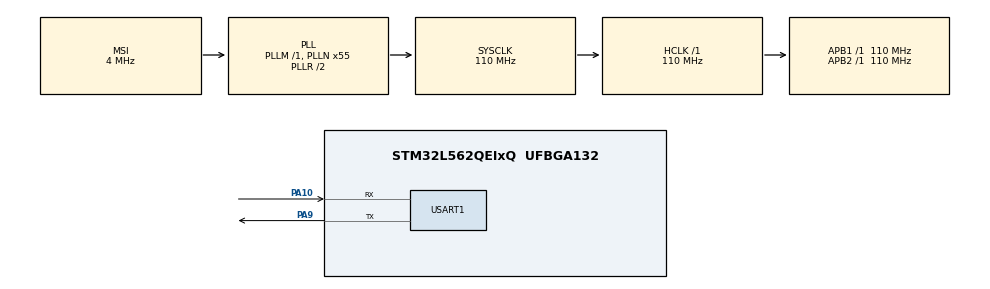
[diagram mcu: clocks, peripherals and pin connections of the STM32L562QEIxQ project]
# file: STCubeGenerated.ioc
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Mcu.Family=STM32L5
Mcu.Name=STM32L562QEIxQ
Mcu.Package=UFBGA132
Mcu.TrustZone=disable
NVIC.PriorityGroup=NVIC_PRIORITYGROUP_3
NVIC.USART1_IRQn=true\:0\:0\:false\:false\:true\:true\:true
PA10.GPIO_Speed=GPIO_SPEED_FREQ_VERY_HIGH
PA10.Mode=Asynchronous
PA10.Signal=USART1_RX
PA9.GPIO_Speed=GPIO_SPEED_FREQ_VERY_HIGH
PA9.Mode=Asynchronous
PA9.Signal=USART1_TX
ProjectManager.HeapSize=0x200
ProjectManager.StackSize=0x400
ProjectManager.TargetToolchain=MDK-ARM V5.27
RCC.AHBFreq_Value=110000000
RCC.APB1Freq_Value=110000000
RCC.APB1TimFreq_Value=110000000
RCC.APB2Freq_Value=110000000
RCC.APB2TimFreq_Value=110000000
RCC.CortexFreq_Value=110000000
RCC.HCLKFreq_Value=110000000
RCC.HSE_VALUE=16000000
RCC.HSI48_VALUE=48000000
RCC.HSI_VALUE=16000000
RCC.LSE_VALUE=32768
RCC.MSI_VALUE=4000000
RCC.PLLN=55
RCC.SYSCLKFreq_VALUE=110000000
RCC.SYSCLKSource=RCC_SYSCLKSOURCE_PLLCLK
RCC.VCOOutputFreq_Value=220000000
USART1.VirtualMode-Asynchronous=VM_ASYNC
VP_ICACHE_VS_ICACHE.Mode=DefaultMode
VP_PWR_VS_DBSignals.Mode=DisableDeadBatterySignals
board=custom

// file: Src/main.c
/* USER CODE BEGIN Header */
/**
  ******************************************************************************
  * @file           : main.c
  * @brief          : Main program body
  ******************************************************************************
  * @attention
  *
  * <h2><center>&copy; Copyright (c) 2020 STMicroelectronics.
  * All rights reserved.</center></h2>
  *
  * This software component is licensed by ST under BSD 3-Clause license,
  * the "License"; You may not use this file except in compliance with the
  * License. You may obtain a copy of the License at:
  *                        opensource.org/licenses/BSD-3-Clause
  *
  ******************************************************************************
  */
/* USER CODE END Header */

#include "main.h"

/* USER CODE BEGIN PD */
#ifdef  RTE_TFM_TEST_FRAMEWORK_NS
#define main main0
#endif
#define DELAY_SLOW_CYCLES       2U
/* USER CODE END PD */

UART_HandleTypeDef huart1;

void SystemClock_Config(void);
static void MX_GPIO_Init(void);
static void MX_ICACHE_Init(void);
static void MX_USART1_UART_Init(void);

/* USER CODE BEGIN 0 */

/**
  * Override default HAL_GetTick function
  */

volatile uint32_t DEBUG_Tick = 0;
uint32_t HAL_GetTick (void) {
  static uint32_t ticks = 0U;
         uint32_t i;

  if (osKernelGetState () == osKernelRunning) {
    DEBUG_Tick = osKernelGetTickCount ();
    return ((uint32_t)osKernelGetTickCount ());
  }

  /* If Kernel is not running wait approximately 1 ms then increment
     and return auxiliary tick counter value */
  for (i =((SystemCoreClock >> 14U)*DELAY_SLOW_CYCLES); i > 0U; i--) {
    __NOP(); __NOP(); __NOP(); __NOP(); __NOP(); __NOP();
    __NOP(); __NOP(); __NOP(); __NOP(); __NOP(); __NOP();
  }
  return ++ticks;
}

/* USER CODE END 0 */

int main(void)
{

  /* MCU Configuration--------------------------------------------------------*/

  /* Reset of all peripherals, Initializes the Flash interface and the Systick. */
  HAL_Init();

  /* Configure the system clock */
  SystemClock_Config();

  /* Initialize all configured peripherals */
  MX_GPIO_Init();
  MX_ICACHE_Init();
  MX_USART1_UART_Init();

  /* Infinite loop */
  /* USER CODE BEGIN WHILE */
  while (1)
  {
#ifdef  RTE_TFM_TEST_FRAMEWORK_NS
    break;
#endif
    /* USER CODE END WHILE */

    /* USER CODE BEGIN 3 */
  }
  return 0;
  /* USER CODE END 3 */
}

void SystemClock_Config(void)
{
  RCC_OscInitTypeDef RCC_OscInitStruct = {0};
  RCC_ClkInitTypeDef RCC_ClkInitStruct = {0};

  /** Configure the main internal regulator output voltage
  */
  if (HAL_PWREx_ControlVoltageScaling(PWR_REGULATOR_VOLTAGE_SCALE0) != HAL_OK)
  {
    Error_Handler();
  }
  /** Initializes the CPU, AHB and APB busses clocks
  */
  RCC_OscInitStruct.OscillatorType = RCC_OSCILLATORTYPE_MSI;
  RCC_OscInitStruct.MSIState = RCC_MSI_ON;
  RCC_OscInitStruct.MSICalibrationValue = RCC_MSICALIBRATION_DEFAULT;
  RCC_OscInitStruct.MSIClockRange = RCC_MSIRANGE_6;
  RCC_OscInitStruct.PLL.PLLState = RCC_PLL_ON;
  RCC_OscInitStruct.PLL.PLLSource = RCC_PLLSOURCE_MSI;
  RCC_OscInitStruct.PLL.PLLM = 1;
  RCC_OscInitStruct.PLL.PLLN = 55;
  RCC_OscInitStruct.PLL.PLLP = RCC_PLLP_DIV7;
  RCC_OscInitStruct.PLL.PLLQ = RCC_PLLQ_DIV2;
  RCC_OscInitStruct.PLL.PLLR = RCC_PLLR_DIV2;
  if (HAL_RCC_OscConfig(&RCC_OscInitStruct) != HAL_OK)
  {
    Error_Handler();
  }
  /** Initializes the CPU, AHB and APB busses clocks
  */
  RCC_ClkInitStruct.ClockType = RCC_CLOCKTYPE_HCLK|RCC_CLOCKTYPE_SYSCLK
                              |RCC_CLOCKTYPE_PCLK1|RCC_CLOCKTYPE_PCLK2;
  RCC_ClkInitStruct.SYSCLKSource = RCC_SYSCLKSOURCE_PLLCLK;
  RCC_ClkInitStruct.AHBCLKDivider = RCC_SYSCLK_DIV1;
  RCC_ClkInitStruct.APB1CLKDivider = RCC_HCLK_DIV1;
  RCC_ClkInitStruct.APB2CLKDivider = RCC_HCLK_DIV1;

  if (HAL_RCC_ClockConfig(&RCC_ClkInitStruct, FLASH_LATENCY_5) != HAL_OK)
  {
    Error_Handler();
  }
}

static void MX_ICACHE_Init(void)
{

  /** Enable instruction cache (default 2-ways set associative cache)
  */
  if (HAL_ICACHE_Enable() != HAL_OK)
  {
    Error_Handler();
  }

}

static void MX_USART1_UART_Init(void)
{

  huart1.Instance = USART1;
  huart1.Init.BaudRate = 115200;
  huart1.Init.WordLength = UART_WORDLENGTH_8B;
  huart1.Init.StopBits = UART_STOPBITS_1;
  huart1.Init.Parity = UART_PARITY_NONE;
  huart1.Init.Mode = UART_MODE_TX_RX;
  huart1.Init.HwFlowCtl = UART_HWCONTROL_NONE;
  huart1.Init.OverSampling = UART_OVERSAMPLING_16;
  huart1.Init.OneBitSampling = UART_ONE_BIT_SAMPLE_DISABLE;
  huart1.Init.ClockPrescaler = UART_PRESCALER_DIV1;
  huart1.AdvancedInit.AdvFeatureInit = UART_ADVFEATURE_NO_INIT;
  if (HAL_UART_Init(&huart1) != HAL_OK)
  {
    Error_Handler();
  }
  if (HAL_UARTEx_SetTxFifoThreshold(&huart1, UART_TXFIFO_THRESHOLD_1_8) != HAL_OK)
  {
    Error_Handler();
  }
  if (HAL_UARTEx_SetRxFifoThreshold(&huart1, UART_RXFIFO_THRESHOLD_1_8) != HAL_OK)
  {
    Error_Handler();
  }
  if (HAL_UARTEx_DisableFifoMode(&huart1) != HAL_OK)
  {
    Error_Handler();
  }

}

static void MX_GPIO_Init(void)
{

  /* GPIO Ports Clock Enable */
  __HAL_RCC_GPIOA_CLK_ENABLE();

}

/* USER CODE BEGIN 4 */
#ifdef RTE_TFM_TEST_FRAMEWORK_NS
extern ARM_DRIVER_USART NS_DRIVER_STDIO;
int32_t tfm_ns_platform_init(void)
{
    int32_t ret;

    main();

    ret = NS_DRIVER_STDIO.Initialize(NULL);
    if (ret != ARM_DRIVER_OK) {
      return ARM_DRIVER_ERROR;
    }

    ret = NS_DRIVER_STDIO.PowerControl(ARM_POWER_FULL);
    if (ret != ARM_DRIVER_OK) {
      return ARM_DRIVER_ERROR;
    }

    ret = NS_DRIVER_STDIO.Control(ARM_USART_MODE_ASYNCHRONOUS,
                                  DEFAULT_UART_BAUDRATE);
    if (ret != ARM_DRIVER_OK) {
      return ARM_DRIVER_ERROR;
    }

    (void)NS_DRIVER_STDIO.Control(ARM_USART_CONTROL_TX, 1);

    return ARM_DRIVER_OK;
}
#endif
/* USER CODE END 4 */

void Error_Handler(void)
{
}

/************************ (C) COPYRIGHT STMicroelectronics *****END OF FILE****/
